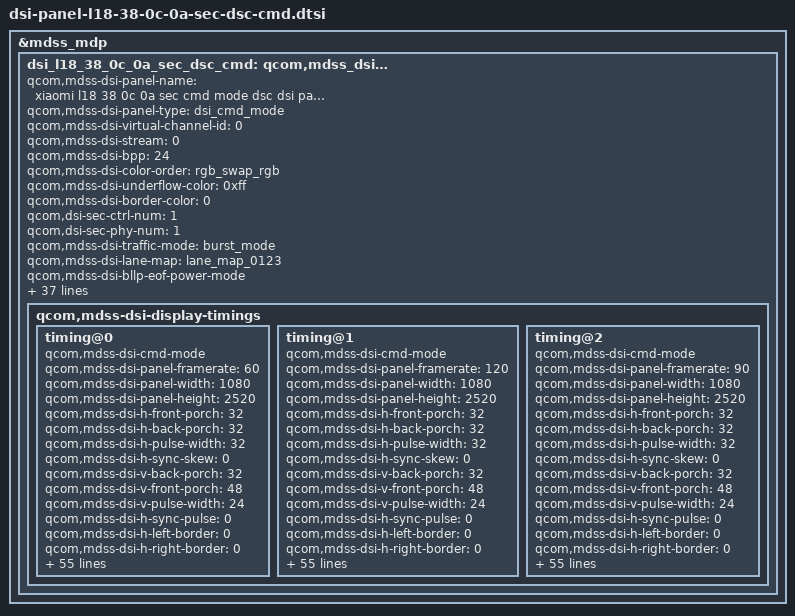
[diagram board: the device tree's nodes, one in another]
&mdss_mdp {
	dsi_l18_38_0c_0a_sec_dsc_cmd: qcom,mdss_dsi_l18_38_0c_0a_sec_dsc_cmd {
		qcom,mdss-dsi-panel-name = "xiaomi l18 38 0c 0a sec cmd mode dsc dsi panel";
		qcom,mdss-dsi-panel-type = "dsi_cmd_mode";
		qcom,mdss-dsi-virtual-channel-id = <0>;
		qcom,mdss-dsi-stream = <0>;
		qcom,mdss-dsi-bpp = <24>;
		qcom,mdss-dsi-color-order = "rgb_swap_rgb";
		qcom,mdss-dsi-underflow-color = <0xff>;
		qcom,mdss-dsi-border-color = <0>;
		qcom,dsi-sec-ctrl-num = <1>;
		qcom,dsi-sec-phy-num = <1>;

		qcom,mdss-dsi-traffic-mode = "burst_mode";
		qcom,mdss-dsi-lane-map = "lane_map_0123";
		qcom,mdss-dsi-bllp-eof-power-mode;
		qcom,mdss-dsi-bllp-power-mode;
		qcom,mdss-dsi-lane-0-state;
		qcom,mdss-dsi-lane-1-state;
		qcom,mdss-dsi-lane-2-state;
		qcom,mdss-dsi-lane-3-state;
		qcom,mdss-dsi-dma-trigger = "trigger_sw";
		qcom,mdss-dsi-mdp-trigger = "none";
		qcom,mdss-dsi-reset-sequence = <0 1>, <1 10>;
		qcom,mdss-pan-physical-width-dimension = <657>;
		qcom,mdss-pan-physical-height-dimension = <1532>;
		qcom,mdss-dsi-te-pin-select = <1>;
		qcom,mdss-dsi-wr-mem-start = <0x2c>;
		qcom,mdss-dsi-wr-mem-continue = <0x3c>;
		qcom,mdss-dsi-te-dcs-command = <1>;
		qcom,mdss-dsi-te-check-enable;
		qcom,mdss-dsi-te-using-te-pin;
		qcom,mdss-dsi-tx-eot-append;
		qcom,mdss-dsi-lp11-init;

		//qcom,mdss-dsi-panel-mode-switch;

		qcom,mdss-dsi-bl-inverted-dbv;
		qcom,bl-update-flag = "delay_until_first_frame";

		qcom,mdss-dsi-dma-schedule-line = <1>;
		qcom,mdss-dsi-dma-schedule-window = <50>;

		qcom,mdss-dsi-panel-hdr-enabled;
		qcom,mdss-dsi-panel-hdr-color-primaries = <14500 15500 32000
			17000 15500 30000 8000 3000>;
		qcom,mdss-dsi-panel-peak-brightness = <4200000>;
		qcom,mdss-dsi-panel-blackness-level = <3230>;

		qcom,mdss-dsi-display-timings {
			timing@0{
				qcom,mdss-dsi-cmd-mode;
				qcom,mdss-dsi-panel-framerate = <60>;
				qcom,mdss-dsi-panel-width = <1080>;
				qcom,mdss-dsi-panel-height = <2520>;
				qcom,mdss-dsi-h-front-porch = <32>;
				qcom,mdss-dsi-h-back-porch = <32>;
				qcom,mdss-dsi-h-pulse-width = <32>;
				qcom,mdss-dsi-h-sync-skew = <0>;
				qcom,mdss-dsi-v-back-porch = <32>;
				qcom,mdss-dsi-v-front-porch = <48>;
				qcom,mdss-dsi-v-pulse-width = <24>;
				qcom,mdss-dsi-h-sync-pulse = <0>;
				qcom,mdss-dsi-h-left-border = <0>;
				qcom,mdss-dsi-h-right-border = <0>;
				qcom,mdss-dsi-v-top-border = <0>;
				qcom,mdss-dsi-v-bottom-border = <0>;
				qcom,mdss-dsi-panel-clockrate = <832000000>;
				qcom,mdss-dsi-panel-jitter = <0x5 0x1>;
				qcom,mdss-mdp-transfer-time-us = <7300>;

				qcom,mdss-dsi-on-command = [
					/* DSC Setting */
					39 00 00 00 00 00 5A 9E 11 00 00 89 30
					   80 09 D8 04 38 00 28 02 1C 02 1C 02
					   00 02 3B 00 20 03 92 00 07 00 0E 02
					   E0 02 8B 18 00 10 F0 03 0C 20 00 06
					   0B 0B 33 0E 1C 2A 38 46 54 62 69 70
					   77 79 7B 7D 7E 01 02 01 00 09 40 09
					   BE 19 FC 19 FA 19 F8 1A 38 1A 78 1A
					   B6 2A B6 2A F4 2A F4 4B 34 63 74 00
					/* Compression Enable */
					15 00 00 00 00 00 02 9D 01
					/* Sleep Out */
					05 00 00 00 64 00 02 11 00
					/* Common Setting */
					/* TE(Vsync) On */
					15 00 00 00 00 00 02 35 00
					/* CASET/PASET Setting 1080*2520 */
					39 00 00 40 00 00 05 2A 00 00 04 37
					39 00 00 00 00 00 05 2B 00 00 09 D7
					/* Frequency Select 60.5Hz */
					39 00 00 40 00 00 03 F0 5A 5A
					15 00 00 40 00 00 02 60 08
					39 00 00 40 00 00 04 B0 00 16 F2
					39 00 00 40 00 00 03 F2 01 60
					39 00 00 40 00 00 04 B0 01 D4 CB
					15 00 00 40 00 00 02 CB 1A
					39 00 00 40 00 00 04 B0 01 DA CB
					15 00 00 40 00 00 02 CB 1A
					15 00 00 40 00 00 02 F7 0F
					39 00 00 00 00 00 03 F0 A5 A5
					/* Dimming Setting*/
					39 00 00 40 00 00 03 F0 5A 5A
					39 00 00 40 00 00 04 B0 00 0D 94
					15 00 00 40 00 00 02 94 20
					15 00 00 40 00 00 02 53 28
					39 00 00 40 00 00 03 51 00 00
					15 00 00 40 00 00 02 F7 0F
					39 00 00 00 00 00 03 F0 A5 A5
					/* SPR 1D/2D Mode (2D) */
					39 00 00 40 00 00 03 F0 5A 5A
					39 00 00 40 00 00 04 B0 01 64 92
					39 00 00 40 00 00 02 92 70
					39 00 00 00 00 00 03 F0 A5 A5
					/*Erro Flag Setting*/
					39 00 00 40 00 00 03 F0 5A 5A
					15 00 00 40 00 00 02 E5 15
					39 00 00 40 00 00 04 B0 00 3D F4
					15 00 00 40 00 00 02 F4 F0
					39 00 00 40 00 00 05 ED 43 49 42 03
					39 00 00 00 00 00 03 F0 A5 A5
					/* DCDC Setting (SET PIN = LOW) */
					39 00 00 40 00 00 03 F0 5A 5A
					39 00 00 40 00 00 04 B0 00 0A B1
					39 00 00 40 00 00 04 B1 18 48 20
					39 00 00 00 00 00 03 F0 A5 A5
					/* flat dimming */
					39 00 00 40 00 00 03 F0 5A 5A
					39 00 00 40 00 00 04 B0 02 7E 92
					15 00 00 40 00 00 02 92 0F
					39 00 00 00 00 00 03 F0 A5 A5
					/* Display On */
					05 00 00 00 00 00 02 29 00
				];
				qcom,mdss-dsi-on-command-state = "dsi_lp_mode";
				qcom,mdss-dsi-off-command = [
					05 00 00 00 00 00 02 28 00
					05 00 00 00 78 00 02 10 00
				];
				qcom,mdss-dsi-off-command-state = "dsi_lp_mode";

				qcom,mdss-dsi-timing-switch-command = [
					/*Frequency Select 60.5 */
					39 00 00 40 00 00 03 F0 5A 5A
					15 00 00 40 00 00 02 60 08
					39 00 00 40 00 00 04 B0 00 16 F2
					39 00 00 40 00 00 03 F2 01 60
					39 00 00 40 00 00 04 B0 01 D4 CB
					15 00 00 40 00 00 02 CB 1A
					39 00 00 40 00 00 04 B0 01 DA CB
					15 00 00 40 00 00 02 CB 1A
					15 00 00 40 00 00 02 F7 0F
					39 00 00 00 00 00 03 F0 A5 A5
				];
				qcom,mdss-dsi-timing-switch-command-state = "dsi_hs_mode";

				qcom,mdss-dsi-nolp-command = [
					39 00 00 40 00 00 03 F0 5A 5A
					15 00 00 40 00 00 02 60 08
					15 00 00 40 00 00 02 53 20
					39 00 00 40 00 00 03 51 00 00
					15 00 00 40 00 00 02 F7 0F
					39 00 00 00 22 00 03 F0 A5 A5
				];
				qcom,mdss-dsi-nolp-command-state = "dsi_lp_mode";

				qcom,compression-mode = "dsc";
				qcom,mdss-dsc-slice-height = <40>;
				qcom,mdss-dsc-slice-width = <540>;
				qcom,mdss-dsc-slice-per-pkt = <2>;
				qcom,mdss-dsc-bit-per-component = <8>;
				qcom,mdss-dsc-bit-per-pixel = <8>;
				qcom,mdss-dsc-block-prediction-enable;
			};

			timing@1{
				qcom,mdss-dsi-cmd-mode;
				qcom,mdss-dsi-panel-framerate = <120>;
				qcom,mdss-dsi-panel-width = <1080>;
				qcom,mdss-dsi-panel-height = <2520>;
				qcom,mdss-dsi-h-front-porch = <32>;
				qcom,mdss-dsi-h-back-porch = <32>;
				qcom,mdss-dsi-h-pulse-width = <32>;
				qcom,mdss-dsi-h-sync-skew = <0>;
				qcom,mdss-dsi-v-back-porch = <32>;
				qcom,mdss-dsi-v-front-porch = <48>;
				qcom,mdss-dsi-v-pulse-width = <24>;
				qcom,mdss-dsi-h-sync-pulse = <0>;
				qcom,mdss-dsi-h-left-border = <0>;
				qcom,mdss-dsi-h-right-border = <0>;
				qcom,mdss-dsi-v-top-border = <0>;
				qcom,mdss-dsi-v-bottom-border = <0>;
				qcom,mdss-dsi-panel-clockrate = <832000000>;
				qcom,mdss-dsi-panel-jitter = <0x5 0x1>;
				qcom,mdss-mdp-transfer-time-us = <7300>;

				qcom,mdss-dsi-on-command = [
					/* DSC Setting */
					39 00 00 00 00 00 5A 9E 11 00 00 89 30
					   80 09 D8 04 38 00 28 02 1C 02 1C 02
					   00 02 3B 00 20 03 92 00 07 00 0E 02
					   E0 02 8B 18 00 10 F0 03 0C 20 00 06
					   0B 0B 33 0E 1C 2A 38 46 54 62 69 70
					   77 79 7B 7D 7E 01 02 01 00 09 40 09
					   BE 19 FC 19 FA 19 F8 1A 38 1A 78 1A
					   B6 2A B6 2A F4 2A F4 4B 34 63 74 00
					/* Compression Enable */
					15 00 00 00 00 00 02 9D 01
					/* Sleep Out */
					05 00 00 00 64 00 02 11 00
					/* Common Setting */
					/* TE(Vsync) On */
					15 00 00 00 00 00 02 35 00
					/* CASET/PASET Setting 1080*2520 */
					39 00 00 40 00 00 05 2A 00 00 04 37
					39 00 00 00 00 00 05 2B 00 00 09 D7
					/* Frequency Select 120Hz */
					39 00 00 40 00 00 03 F0 5A 5A
					15 00 00 40 00 00 02 60 00
					39 00 00 40 00 00 04 B0 00 16 F2
					39 00 00 40 00 00 03 F2 01 60
					39 00 00 40 00 00 04 B0 01 D4 CB
					15 00 00 40 00 00 02 CB 1A
					39 00 00 40 00 00 04 B0 01 DA CB
					15 00 00 40 00 00 02 CB 1A
					15 00 00 40 00 00 02 F7 0F
					39 00 00 00 00 00 03 F0 A5 A5
					/* Dimming Setting*/
					39 00 00 40 00 00 03 F0 5A 5A
					39 00 00 40 00 00 04 B0 00 0D 94
					15 00 00 40 00 00 02 94 20
					15 00 00 40 00 00 02 53 28
					39 00 00 40 00 00 03 51 00 00
					15 00 00 40 00 00 02 F7 0F
					39 00 00 00 00 00 03 F0 A5 A5
					/* SPR 1D/2D Mode (2D) */
					39 00 00 40 00 00 03 F0 5A 5A
					39 00 00 40 00 00 04 B0 01 64 92
					39 00 00 40 00 00 02 92 70
					39 00 00 00 00 00 03 F0 A5 A5
					/*Erro Flag Setting*/
					39 00 00 40 00 00 03 F0 5A 5A
					15 00 00 40 00 00 02 E5 15
					39 00 00 40 00 00 04 B0 00 3D F4
					15 00 00 40 00 00 02 F4 F0
					39 00 00 40 00 00 05 ED 43 49 42 03
					39 00 00 00 00 00 03 F0 A5 A5
					/* DCDC Setting (SET PIN = LOW) */
					39 00 00 40 00 00 03 F0 5A 5A
					39 00 00 40 00 00 04 B0 00 0A B1
					39 00 00 40 00 00 04 B1 18 48 20
					39 00 00 00 00 00 03 F0 A5 A5
					/* flat dimming */
					39 00 00 40 00 00 03 F0 5A 5A
					39 00 00 40 00 00 04 B0 02 7E 92
					15 00 00 40 00 00 02 92 0F
					39 00 00 00 00 00 03 F0 A5 A5
					/* Display On */
					05 00 00 00 00 00 02 29 00
				];
				qcom,mdss-dsi-on-command-state = "dsi_lp_mode";
				qcom,mdss-dsi-off-command = [
					05 00 00 00 00 00 02 28 00
					05 00 00 00 78 00 02 10 00
				];
				qcom,mdss-dsi-off-command-state = "dsi_lp_mode";

				qcom,mdss-dsi-timing-switch-command = [
					39 00 00 40 00 00 03 F0 5A 5A
					15 00 00 40 00 00 02 60 00
					39 00 00 40 00 00 04 B0 00 16 F2
					39 00 00 40 00 00 03 F2 01 60
					39 00 00 40 00 00 04 B0 01 D4 CB
					15 00 00 40 00 00 02 CB 1A
					39 00 00 40 00 00 04 B0 01 DA CB
					15 00 00 40 00 00 02 CB 1A
					15 00 00 40 00 00 02 F7 0F
					39 00 00 00 00 00 03 F0 A5 A5
				];
				qcom,mdss-dsi-timing-switch-command-state = "dsi_hs_mode";

				qcom,mdss-dsi-nolp-command = [
					39 00 00 40 00 00 03 F0 5A 5A
					15 00 00 40 00 00 02 60 00
					15 00 00 40 00 00 02 53 20
					39 00 00 40 00 00 03 51 00 00
					15 00 00 40 00 00 02 F7 0F
					39 00 00 00 22 00 03 F0 A5 A5
				];
				qcom,mdss-dsi-nolp-command-state = "dsi_lp_mode";

				qcom,compression-mode = "dsc";
				qcom,mdss-dsc-slice-height = <40>;
				qcom,mdss-dsc-slice-width = <540>;
				qcom,mdss-dsc-slice-per-pkt = <2>;
				qcom,mdss-dsc-bit-per-component = <8>;
				qcom,mdss-dsc-bit-per-pixel = <8>;
				qcom,mdss-dsc-block-prediction-enable;
			};
			timing@2{
				qcom,mdss-dsi-cmd-mode;
				qcom,mdss-dsi-panel-framerate = <90>;
				qcom,mdss-dsi-panel-width = <1080>;
				qcom,mdss-dsi-panel-height = <2520>;
				qcom,mdss-dsi-h-front-porch = <32>;
				qcom,mdss-dsi-h-back-porch = <32>;
				qcom,mdss-dsi-h-pulse-width = <32>;
				qcom,mdss-dsi-h-sync-skew = <0>;
				qcom,mdss-dsi-v-back-porch = <32>;
				qcom,mdss-dsi-v-front-porch = <48>;
				qcom,mdss-dsi-v-pulse-width = <24>;
				qcom,mdss-dsi-h-sync-pulse = <0>;
				qcom,mdss-dsi-h-left-border = <0>;
				qcom,mdss-dsi-h-right-border = <0>;
				qcom,mdss-dsi-v-top-border = <0>;
				qcom,mdss-dsi-v-bottom-border = <0>;
				qcom,mdss-dsi-panel-clockrate = <832000000>;
				qcom,mdss-dsi-panel-jitter = <0x5 0x1>;
				qcom,mdss-mdp-transfer-time-us = <7300>;

				qcom,mdss-dsi-on-command = [
					/* DSC Setting */
					39 00 00 00 00 00 5A 9E 11 00 00 89 30
					   80 09 D8 04 38 00 28 02 1C 02 1C 02
					   00 02 3B 00 20 03 92 00 07 00 0E 02
					   E0 02 8B 18 00 10 F0 03 0C 20 00 06
					   0B 0B 33 0E 1C 2A 38 46 54 62 69 70
					   77 79 7B 7D 7E 01 02 01 00 09 40 09
					   BE 19 FC 19 FA 19 F8 1A 38 1A 78 1A
					   B6 2A B6 2A F4 2A F4 4B 34 63 74 00
					/* Compression Enable */
					15 00 00 00 00 00 02 9D 01
					/* Sleep Out */
					05 00 00 00 64 00 02 11 00
					/* Common Setting */
					/* TE(Vsync) On */
					15 00 00 00 00 00 02 35 00
					/* CASET/PASET Setting 1080*2520 */
					39 00 00 40 00 00 05 2A 00 00 04 37
					39 00 00 00 00 00 05 2B 00 00 09 D7
					/* Frequency Select 90Hz */
					39 00 00 40 00 00 03 F0 5A 5A
					15 00 00 40 00 00 02 60 00
					39 00 00 40 00 00 04 B0 00 16 F2
					39 00 00 40 00 00 03 F2 01 D6
					39 00 00 40 00 00 04 B0 01 D4 CB
					15 00 00 40 00 00 02 CB 37
					39 00 00 40 00 00 04 B0 01 DA CB
					15 00 00 40 00 00 02 CB 37
					15 00 00 40 00 00 02 F7 0F
					39 00 00 00 00 00 03 F0 A5 A5
					/* Dimming Setting*/
					39 00 00 40 00 00 03 F0 5A 5A
					39 00 00 40 00 00 04 B0 00 0D 94
					15 00 00 40 00 00 02 94 20
					15 00 00 40 00 00 02 53 28
					39 00 00 40 00 00 03 51 00 00
					15 00 00 40 00 00 02 F7 0F
					39 00 00 00 00 00 03 F0 A5 A5
					/* SPR 1D/2D Mode (2D) */
					39 00 00 40 00 00 03 F0 5A 5A
					39 00 00 40 00 00 04 B0 01 64 92
					39 00 00 40 00 00 02 92 70
					39 00 00 00 00 00 03 F0 A5 A5
					/*Erro Flag Setting*/
					39 00 00 40 00 00 03 F0 5A 5A
					15 00 00 40 00 00 02 E5 15
					39 00 00 40 00 00 04 B0 00 3D F4
					15 00 00 40 00 00 02 F4 F0
					39 00 00 40 00 00 05 ED 43 49 42 03
					39 00 00 00 00 00 03 F0 A5 A5
					/* DCDC Setting (SET PIN = LOW) */
					39 00 00 40 00 00 03 F0 5A 5A
					39 00 00 40 00 00 04 B0 00 0A B1
					39 00 00 40 00 00 04 B1 18 48 20
					39 00 00 00 00 00 03 F0 A5 A5
					/* flat dimming */
					39 00 00 40 00 00 03 F0 5A 5A
					39 00 00 40 00 00 04 B0 02 7E 92
					15 00 00 40 00 00 02 92 0F
					39 00 00 00 00 00 03 F0 A5 A5
					/* Display On */
					05 00 00 00 00 00 02 29 00];
				qcom,mdss-dsi-on-command-state = "dsi_lp_mode";

				qcom,mdss-dsi-off-command = [
					05 00 00 00 00 00 02 28 00
					05 00 00 00 78 00 02 10 00];
				qcom,mdss-dsi-off-command-state = "dsi_lp_mode";

				qcom,mdss-dsi-timing-switch-command = [
					39 00 00 40 00 00 03 F0 5A 5A
					15 00 00 40 00 00 02 60 00
					39 00 00 40 00 00 04 B0 00 16 F2
					39 00 00 40 00 00 03 F2 01 D6
					39 00 00 40 00 00 04 B0 01 D4 CB
					15 00 00 40 00 00 02 CB 37
					39 00 00 40 00 00 04 B0 01 DA CB
					15 00 00 40 00 00 02 CB 37
					15 00 00 40 00 00 02 F7 0F
					39 00 00 00 00 00 03 F0 A5 A5
				];
				qcom,mdss-dsi-timing-switch-command-state = "dsi_hs_mode";

				qcom,mdss-dsi-nolp-command = [
					39 00 00 40 00 00 03 F0 5A 5A
					15 00 00 40 00 00 02 60 00
					39 00 00 40 00 00 04 B0 00 16 F2
					39 00 00 40 00 00 03 F2 01 D6
					39 00 00 40 00 00 04 B0 01 D4 CB
					15 00 00 40 00 00 02 CB 37
					39 00 00 40 00 00 04 B0 01 DA CB
					15 00 00 40 00 00 02 CB 37
					15 00 00 40 00 00 02 53 20
					15 00 00 40 00 00 02 F7 0F
					39 00 00 00 22 00 03 F0 A5 A5
				];
				qcom,mdss-dsi-nolp-command-state = "dsi_lp_mode";

				qcom,compression-mode = "dsc";
				qcom,mdss-dsc-slice-height = <40>;
				qcom,mdss-dsc-slice-width = <540>;
				qcom,mdss-dsc-slice-per-pkt = <2>;
				qcom,mdss-dsc-bit-per-component = <8>;
				qcom,mdss-dsc-bit-per-pixel = <8>;
				qcom,mdss-dsc-block-prediction-enable;
			};
		};
	};
};

&dsi_l18_38_0c_0a_sec_dsc_cmd {
	/* IRQF_ONESHOT | IRQF_TRIGGER_LOW */
	mi,esd-err-irq-gpio = <&tlmm 60 0x2008>;
	mi,panel-id = <0x004C3138 0x53380C00>;

	mi,panel-on-dimming-delay = <120>;
	mi,doze-hbm-dbv-level = <196>;
	mi,doze-lbm-dbv-level = <22>;
	mi,max-brightness-clone = <16383>;
	mi,mdss-dsi-panel-dc-threshold = <450>;
	mi,dc-feature-enabled;
	mi,thermal-dimming-flag;
	mi,dc-feature-type = "crc_skip_backlight";

	qcom,mdss-dsi-display-timings {
		/* 60 hz */
		timing@0{
			mi,mdss-dsi-dimmingon-command = [15 00 00 00 00 00 02 53 28];
			mi,mdss-dsi-dimmingon-command-state = "dsi_hs_mode";
			mi,mdss-dsi-dimmingoff-command = [15 00 00 00 00 00 02 53 20];
			mi,mdss-dsi-dimmingoff-command-state = "dsi_hs_mode";

			mi,mdss-dsi-hbm-on-command = [
				39 00 00 40 00 00 03 F0 5A 5A
				39 00 00 40 00 00 03 51 07 FF
				15 00 00 40 00 00 02 F7 0F
				39 00 00 00 00 00 03 F0 A5 A5
			];
			mi,mdss-dsi-hbm-on-command-state = "dsi_lp_mode";
			mi,mdss-dsi-hbm-off-command = [
				39 00 00 40 00 00 03 F0 5A 5A
				39 00 00 40 00 00 03 51 07 FF
				15 00 00 40 00 00 02 F7 0F
				39 00 00 00 00 00 03 F0 A5 A5
			];
			mi,mdss-dsi-hbm-off-command-state = "dsi_lp_mode";

			mi,mdss-dsi-doze-hbm-command = [
				39 00 00 40 00 00 03 F0 5A 5A
				15 00 00 40 00 00 02 60 00
				15 00 00 40 00 00 02 53 24
				39 00 00 40 00 00 03 51 07 FF
				15 00 00 40 00 00 02 F7 0F
				39 00 00 00 00 00 03 F0 A5 A5
			];
			mi,mdss-dsi-doze-hbm-command-state = "dsi_lp_mode";
			mi,mdss-dsi-doze-lbm-command = [
				39 00 00 40 00 00 03 F0 5A 5A
				15 00 00 40 00 00 02 60 00
				15 00 00 40 00 00 02 53 24
				39 00 00 40 00 00 03 51 00 AA
				15 00 00 40 00 00 02 F7 0F
				39 00 00 00 00 00 03 F0 A5 A5
			];
			mi,mdss-dsi-doze-lbm-command-state = "dsi_lp_mode";

			mi,mdss-dsi-flat-mode-on-command = [
				39 00 00 40 00 00 03 F0 5A 5A
				39 00 00 40 00 00 04 B0 02 79 92
				15 00 00 40 00 00 02 92 25
				39 00 00 00 00 00 03 F0 A5 A5
			];
			mi,mdss-dsi-flat-mode-on-command-state = "dsi_lp_mode";

			mi,mdss-dsi-flat-mode-off-command = [
				39 00 00 40 00 00 03 F0 5A 5A
				39 00 00 40 00 00 04 B0 02 79 92
				15 00 00 40 00 00 02 92 05
				39 00 00 00 00 00 03 F0 A5 A5
			];
			mi,mdss-dsi-flat-mode-off-command-state = "dsi_lp_mode";
		};
		/* 120 hz */
		timing@1{
			mi,mdss-dsi-dimmingon-command = [15 00 00 00 00 00 02 53 28];
			mi,mdss-dsi-dimmingon-command-state = "dsi_hs_mode";
			mi,mdss-dsi-dimmingoff-command = [15 00 00 00 00 00 02 53 20];
			mi,mdss-dsi-dimmingoff-command-state = "dsi_hs_mode";

			mi,mdss-dsi-hbm-on-command = [
				39 00 00 40 00 00 03 F0 5A 5A
				39 00 00 40 00 00 03 51 07 FF
				15 00 00 40 00 00 02 F7 0F
				39 00 00 00 00 00 03 F0 A5 A5
			];
			mi,mdss-dsi-hbm-on-command-state = "dsi_lp_mode";
			mi,mdss-dsi-hbm-off-command = [
				39 00 00 40 00 00 03 F0 5A 5A
				39 00 00 40 00 00 03 51 07 FF
				15 00 00 40 00 00 02 F7 0F
				39 00 00 00 00 00 03 F0 A5 A5
			];
			mi,mdss-dsi-hbm-off-command-state = "dsi_lp_mode";

			mi,mdss-dsi-doze-hbm-command = [
				39 00 00 40 00 00 03 F0 5A 5A
				15 00 00 40 00 00 02 60 00
				15 00 00 40 00 00 02 53 24
				39 00 00 40 00 00 03 51 07 FF
				15 00 00 40 00 00 02 F7 0F
				39 00 00 00 00 00 03 F0 A5 A5
			];
			mi,mdss-dsi-doze-hbm-command-state = "dsi_lp_mode";
			mi,mdss-dsi-doze-lbm-command = [
				39 00 00 40 00 00 03 F0 5A 5A
				15 00 00 40 00 00 02 60 00
				15 00 00 40 00 00 02 53 24
				39 00 00 40 00 00 03 51 00 AA
				15 00 00 40 00 00 02 F7 0F
				39 00 00 00 00 00 03 F0 A5 A5
			];
			mi,mdss-dsi-doze-lbm-command-state = "dsi_lp_mode";

			mi,mdss-dsi-flat-mode-on-command = [
				39 00 00 40 00 00 03 F0 5A 5A
				39 00 00 40 00 00 04 B0 02 79 92
				15 00 00 40 00 00 02 92 25
				39 00 00 00 00 00 03 F0 A5 A5
			];
			mi,mdss-dsi-flat-mode-on-command-state = "dsi_lp_mode";

			mi,mdss-dsi-flat-mode-off-command = [
				39 00 00 40 00 00 03 F0 5A 5A
				39 00 00 40 00 00 04 B0 02 79 92
				15 00 00 40 00 00 02 92 05
				39 00 00 00 00 00 03 F0 A5 A5
			];
			mi,mdss-dsi-flat-mode-off-command-state = "dsi_lp_mode";
		};
		/* 90 hz */
		timing@2{
			mi,mdss-dsi-dimmingon-command = [15 00 00 00 00 00 02 53 28];
			mi,mdss-dsi-dimmingon-command-state = "dsi_hs_mode";
			mi,mdss-dsi-dimmingoff-command = [15 00 00 00 00 00 02 53 20];
			mi,mdss-dsi-dimmingoff-command-state = "dsi_hs_mode";

			mi,mdss-dsi-hbm-on-command = [
				39 00 00 40 00 00 03 F0 5A 5A
				39 00 00 40 00 00 03 51 07 FF
				15 00 00 40 00 00 02 F7 0F
				39 00 00 00 00 00 03 F0 A5 A5
			];
			mi,mdss-dsi-hbm-on-command-state = "dsi_lp_mode";
			mi,mdss-dsi-hbm-off-command = [
				39 00 00 40 00 00 03 F0 5A 5A
				39 00 00 40 00 00 03 51 07 FF
				15 00 00 40 00 00 02 F7 0F
				39 00 00 00 00 00 03 F0 A5 A5
			];
			mi,mdss-dsi-hbm-off-command-state = "dsi_lp_mode";


			mi,mdss-dsi-doze-hbm-command = [
				39 00 00 40 00 00 03 F0 5A 5A
				15 00 00 40 00 00 02 53 24
				39 00 00 40 00 00 03 51 07 FF
				15 00 00 40 00 00 02 F7 0F
				39 00 00 00 00 00 03 F0 A5 A5
			];
			mi,mdss-dsi-doze-lbm-command = [
				39 00 00 40 00 00 03 F0 5A 5A
				15 00 00 40 00 00 02 53 25
				39 00 00 40 00 00 03 51 00 F6
				15 00 00 40 00 00 02 F7 0F
				39 00 00 00 00 00 03 F0 A5 A5
			];
			mi,mdss-dsi-doze-hbm-command-state = "dsi_lp_mode";
			mi,mdss-dsi-doze-lbm-command-state = "dsi_lp_mode";

			mi,mdss-dsi-flat-mode-on-command = [
				39 00 00 40 00 00 03 F0 5A 5A
				39 00 00 40 00 00 04 B0 02 79 92
				15 00 00 40 00 00 02 92 25
				39 00 00 00 00 00 03 F0 A5 A5
			];
			mi,mdss-dsi-flat-mode-on-command-state = "dsi_lp_mode";

			mi,mdss-dsi-flat-mode-off-command = [
				39 00 00 40 00 00 03 F0 5A 5A
				39 00 00 40 00 00 04 B0 02 79 92
				15 00 00 40 00 00 02 92 05
				39 00 00 00 00 00 03 F0 A5 A5
			];
			mi,mdss-dsi-flat-mode-off-command-state = "dsi_lp_mode";
		};
	};
};

